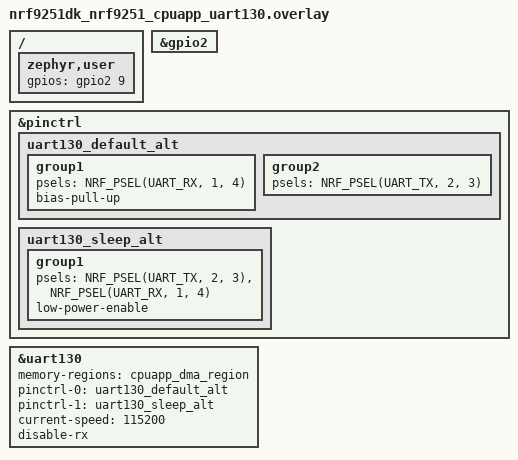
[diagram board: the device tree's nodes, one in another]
/*
 * Test requires wire connection between:
 *  - uart130 TX at P2.03 <-> GPIO input at P2.09
 */

/ {
	zephyr,user {
		gpios = <&gpio2 9 GPIO_ACTIVE_HIGH>;
	};
};

&gpio2 {
	status = "okay";
};

&pinctrl {
	uart130_default_alt: uart130_default_alt {
		group1 {
			psels = <NRF_PSEL(UART_RX, 1, 4)>;
			bias-pull-up;
		};

		group2 {
			psels = <NRF_PSEL(UART_TX, 2, 3)>;
		};
	};

	uart130_sleep_alt: uart130_sleep_alt {
		group1 {
			psels = <NRF_PSEL(UART_TX, 2, 3)>,
				<NRF_PSEL(UART_RX, 1, 4)>;
			low-power-enable;
		};
	};
};

dut: &uart130 {
	status = "okay";
	memory-regions = <&cpuapp_dma_region>;
	pinctrl-0 = <&uart130_default_alt>;
	pinctrl-1 = <&uart130_sleep_alt>;
	pinctrl-names = "default", "sleep";
	current-speed = <115200>;
	disable-rx;
};
